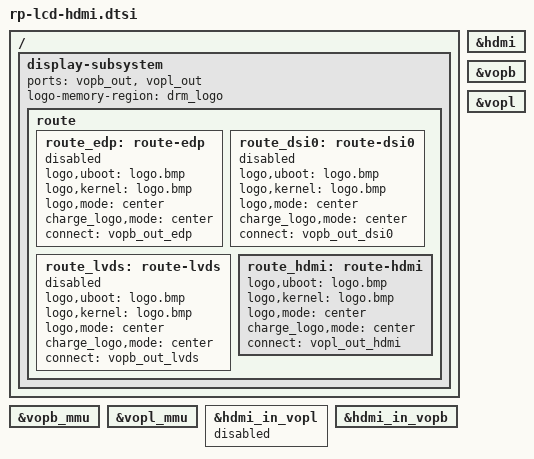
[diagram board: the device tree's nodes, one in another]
/ {
	display-subsystem {
		status = "okay";
		ports = <&vopb_out>, <&vopl_out>;
		logo-memory-region = <&drm_logo>;

		route {
			route_edp: route-edp {
				status = "disabled";
				logo,uboot = "logo.bmp";
				logo,kernel = "logo.bmp";
				logo,mode = "center";
				charge_logo,mode = "center";
				connect = <&vopb_out_edp>;
			};

			route_dsi0: route-dsi0 {
				status = "disabled";
				logo,uboot = "logo.bmp";
				logo,kernel = "logo.bmp";
				logo,mode = "center";
				charge_logo,mode = "center";
				connect = <&vopb_out_dsi0>;
			};

			route_lvds: route-lvds {
				status = "disabled";
				logo,uboot = "logo.bmp";
				logo,kernel = "logo.bmp";
				logo,mode = "center";
				charge_logo,mode = "center";
				connect = <&vopb_out_lvds>;
			};

			route_hdmi: route-hdmi {
				status = "okay";
				logo,uboot = "logo.bmp";
				logo,kernel = "logo.bmp";
				logo,mode = "center";
				charge_logo,mode = "center";
				connect = <&vopl_out_hdmi>;
			};
		};
	};
};

&hdmi {
        #address-cells = <1>;
        #size-cells = <0>;
        #sound-dai-cells = <0>;
        status = "okay";
};

&route_hdmi {
        status = "okay";
};

&vopb {
	status = "okay";
};

&vopb_mmu {
	status = "okay";
};

&vopl {
	status = "okay";
};

&vopl_mmu {
	status = "okay";
};


&hdmi_in_vopl {
        status = "disabled";
};
&hdmi_in_vopb {
        status = "okay";
};
